# ASR6601 register map
Vendor: ASR Microelectronics; Series: ASR6601; File version: 1.1
CPU: CM4 r0p1, little endian, no MPU, FPU, VTOR, 3 interrupt priority bits
Registers are 32-bit, read-write, no defined reset value unless marked. A register's access mark holds for its fields unless they carry their own. Offsets are from the block's base; [hi:lo] are bit positions; {n}, {i} and the like mark numbered series.

## AFEC — Analog front-end controller digital registers
Base 0x40008200
0x00 CR — control register
0x04 INT_SR — interrupt status register
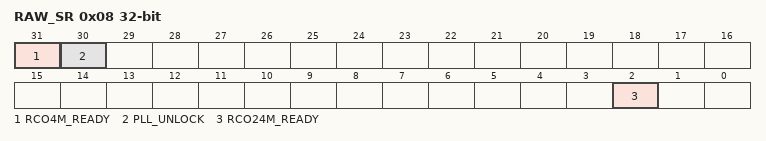
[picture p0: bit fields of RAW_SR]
0x08 RAW_SR ro — raw status register
  [31] RCO4M_READY, [30] PLL_UNLOCK, [2] RCO24M_READY

## LORAC — LoRa controller interface
Base 0x40009000
0x00 SSP_CR0 — ssp control register 0
0x04 SSP_CR1 — ssp control register 1
0x08 SSP_DR — ssp data register
0x0C SSP_SR ro — ssp status register
0x10 SSP_CPSR — ssp clock prescale register
0x14 SSP_IMSC — ssp interrupt mask set or clear register
0x18 SSP_RIS ro — ssp raw interrupt status register
0x1C SSP_MIS ro — ssp masked interrupt status register
0x20 SSP_ICR — ssp interrupt clear register
0x24 SSP_DMA_CR — ssp DMA control register
0x100 CR0 — control register 0
0x104 CR1 — control register 1
0x108 SR ro — status register
0x10C NSS_CR — nss control register
0x110 SCK_CR — sck control register
0x114 MOSI_CR — mosi control register
0x118 MISO_SR — miso control register

## TIMER0
Base 0x4000A000
Same registers: TIMER2 0x4000B000, TIMER1 0x4001A000, TIMER3 0x4001B000
0x00 CR1 — TIMER control register 1, Address
0x04 CR2 — TIMER control register 2, Address
0x08 SMCR — TIMER slave Mode Control register, Address
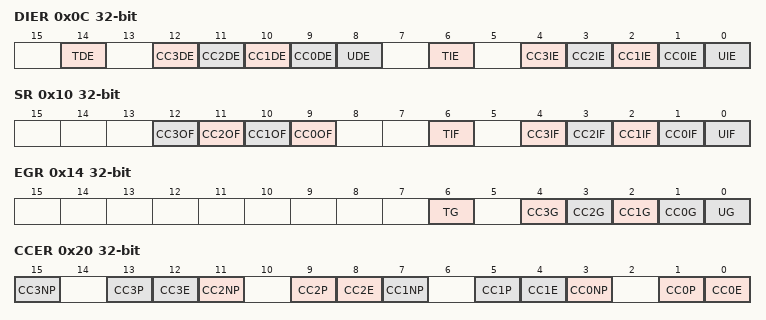
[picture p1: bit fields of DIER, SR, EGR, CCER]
0x0C DIER — TIMER DMA/interrupt enable register, Address
  [14] TDE, [n+9] CC{n}DE (n=0..3), [8] UDE, [6] TIE, [n+1] CC{n}IE (n=0..3), [0] UIE
0x10 SR — TIMER status register, Address
  [n+9] CC{n}OF (n=0..3), [6] TIF, [n+1] CC{n}IF (n=0..3), [0] UIF
0x14 EGR wo — TIMER event generation register, Address
  [6] TG, [n+1] CC{n}G (n=0..3), [0] UG
0x18 CCMR1 — TIMER capture/compare mode register 1, Address
0x1C CCMR2 — TIMER capture/compare mode register 2, Address
0x20 CCER — TIMER capture/compare enable register, Address
  [4n+3] CC{n}NP (n=0..3), [4n+1] CC{n}P (n=0..3), [4n] CC{n}E (n=0..3)
0x24 CNT — TIMER counter register, Address
0x28 PSC — TIMER prescaler register, Address
0x2C ARR — TIMER auto-reload register, Address
{0x34+4i} CCR{i} (i=0..3) — TIMER capture/compare register {i}, Address
0x48 DCR — TIMER DMA control register, Address
  [3] DBL_POSITION
0x4C DMAR — TIMER DMA address for full transfer register, Address
0x50 OR — TIMER option register, Address

## BSTIMER0
Base 0x4000C000
Same registers: BSTIMER1 0x4001C000
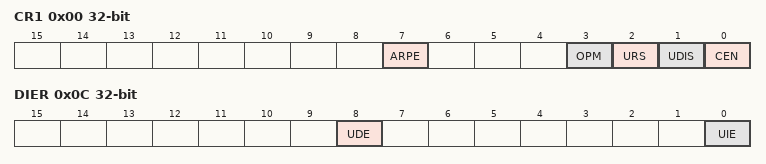
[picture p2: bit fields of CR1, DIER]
0x00 CR1 — control register 1
  [7] ARPE, [3] OPM, [2] URS, [1] UDIS, [0] CEN
0x04 CR2 — control register 2
0x0C DIER — DMA/interrupt enable register
  [8] UDE, [0] UIE
0x10 SR ro — status register
  [0] UIF
0x14 EGR wo — event generation register
  [0] UG
0x24 CNT — counter
0x28 PSC — prescaler
0x2C ARR — auto-reload register

## LPTIMER0
Base 0x4000D000
Same registers: LPTIMER1 0x4000D800
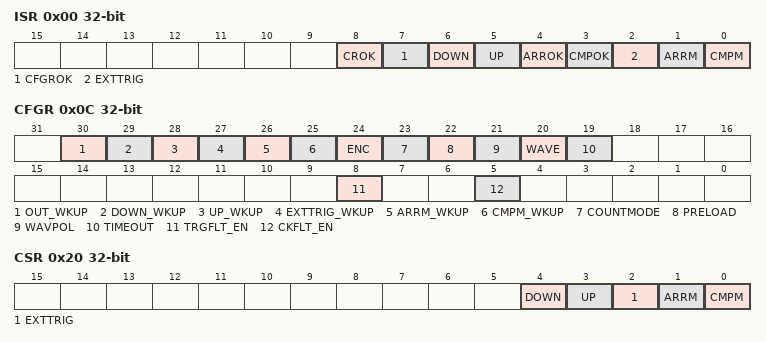
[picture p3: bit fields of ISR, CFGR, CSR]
0x00 ISR ro — LPTIMER flag and status register
  [8] CROK, [7] CFGROK, [6] DOWN, [5] UP, [4] ARROK, [3] CMPOK, [2] EXTTRIG, [1] ARRM, [0] CMPM
0x04 ICR wo — LPTIMER flag clear register
0x08 IER — LPTIMER interrupt enable register
0x0C CFGR — LPTIMER configuration register
  [30] OUT_WKUP, [29] DOWN_WKUP, [28] UP_WKUP, [27] EXTTRIG_WKUP, [26] ARRM_WKUP, [25] CMPM_WKUP, [24] ENC, [23] COUNTMODE, [22] PRELOAD, [21] WAVPOL, [20] WAVE, [19] TIMEOUT, [8] TRGFLT_EN, [5] CKFLT_EN
0x10 CR — LPTIMER control register
  [0] ENABLE
0x14 CMP — LPTIMER compare register
0x18 ARR — LPTIMER autoreload register
0x1C CNT ro — LPTIMER counter register
0x20 CSR ro — LPTIMER CSR register
  [4] DOWN, [3] UP, [2] EXTTRIG, [1] ARRM, [0] CMPM
0x24 SR1 ro — LPTIMER SR1 register

## RTC — Real-time clock
Base 0x4000E000
0x00 CTRL — control register
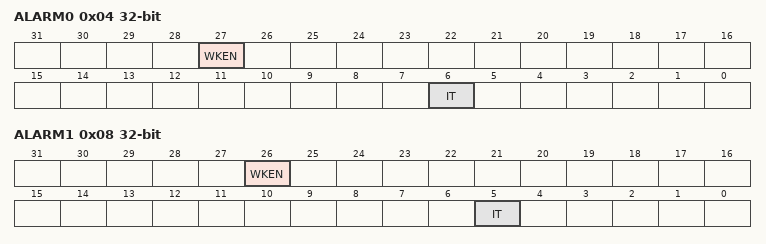
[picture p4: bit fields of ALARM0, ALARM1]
0x04 ALARM0
  [27] WKEN, [6] IT
0x08 ALARM1
  [26] WKEN, [5] IT
0x0C PPM_ADJUST — ppm adjust value
0x10 CALENDAR — time hour/minute/second
0x14 CALENDAR_H — time year/month/date
0x18 CYC_MAX — cyc max value
0x1C SR — status register
0x20 ASYN_DATA ro — asynchronization time hour/minute/second
0x24 ASYN_DATA_H ro — asynchronization time year/month/date
0x28 CR1 — control register 1
0x2C SR1 — status register 1
0x30 CR2 — control register 2
0x34 SUB_SECOND_CNT ro — subsecond counter
0x38 CYC_CNT ro — cyc counter
0x3C ALARM0_SUBSECOND
0x40 ALARM1_SUBSECOND
0x44 CALENDAR_R — read time hour/minute/second
0x48 CALENDAR_R_H — read time year/month/date
